# MKM33ZA5 register map
Vendor: Freescale Semiconductor, Inc.; Series: Kinetis_M; File version: 1.6
CPU: CM0PLUS r0p0, little endian, no MPU, no FPU, VTOR, 2 interrupt priority bits
Registers are 8-bit, read-write, reset 0x0 unless marked. A register's access mark holds for its fields unless they carry their own. Offsets are from the block's base; [hi:lo] are bit positions; {n}, {i} and the like mark numbered series; 'fields as' and 'values as' point back to an identical list.

## NVIC — Nested Vectored Interrupt Controller
Base 0xE000E100
0x00 NVIC_ISER 32-bit — Interrupt Set Enable Register
  [31:0] SETENA — Interrupt set enable bits
0x80 NVIC_ICER 32-bit — Interrupt Clear Enable Register
  [31:0] CLRENA — Interrupt clear-enable bits
0x100 NVIC_ISPR 32-bit — Interrupt Set Pending Register
  [31:0] SETPEND — Interrupt set-pending bits
0x180 NVIC_ICPR 32-bit — Interrupt Clear Pending Register
  [31:0] CLRPEND — Interrupt clear-pending bits
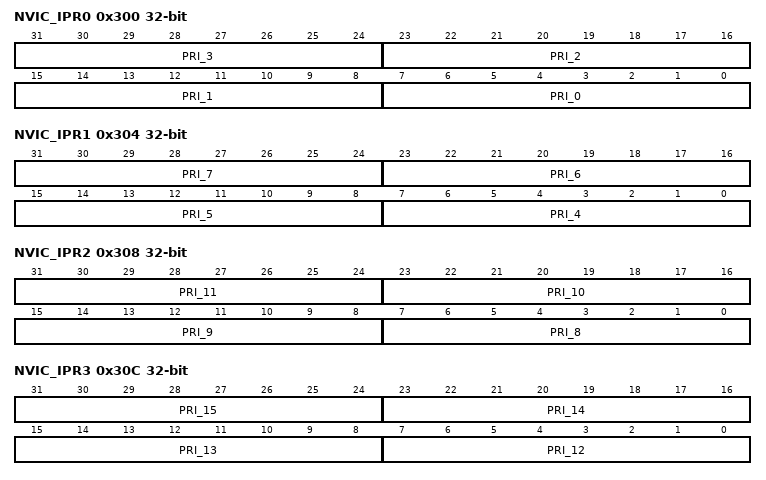
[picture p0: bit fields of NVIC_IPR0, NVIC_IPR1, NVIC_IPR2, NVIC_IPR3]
0x300 NVIC_IPR0 32-bit — Interrupt Priority Register n
  [8n+7:8n] PRI_{n} (n=0..3) — Priority of interrupt {n}
0x304 NVIC_IPR1 32-bit — Interrupt Priority Register n
  [8n-25:8n-32] PRI_{n} (n=4..7) — Priority of interrupt {n}
0x308 NVIC_IPR2 32-bit — Interrupt Priority Register n
  [8n-57:8n-64] PRI_{n} (n=8..11) — Priority of interrupt {n}
0x30C NVIC_IPR3 32-bit — Interrupt Priority Register n
  [31:24] PRI_15 — Priority of interrupt 15
  [23:16] PRI_14 — Priority of interrupt 14
  [15:8] PRI_13 — Priority of interrupt 12
  [7:0] PRI_12 — Priority of interrupt 11
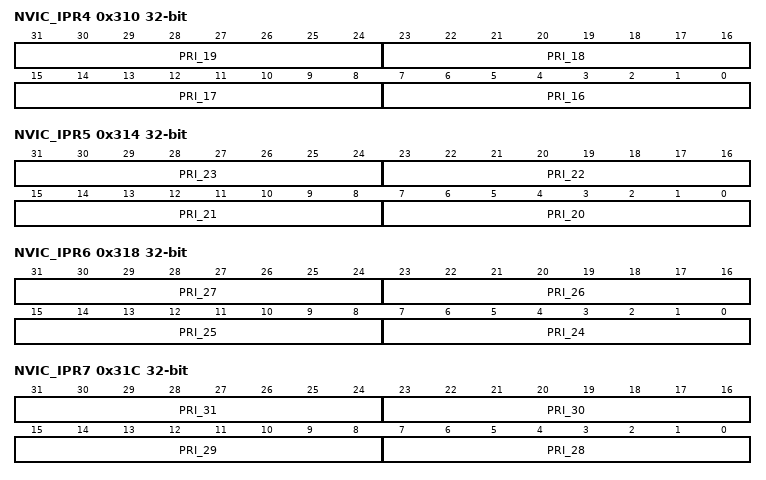
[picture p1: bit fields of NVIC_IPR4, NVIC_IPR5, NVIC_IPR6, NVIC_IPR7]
0x310 NVIC_IPR4 32-bit — Interrupt Priority Register n
  [8n-121:8n-128] PRI_{n} (n=16..19) — Priority of interrupt {n+1}
0x314 NVIC_IPR5 32-bit — Interrupt Priority Register n
  [31:24] PRI_23 — Priority of interrupt 23
  [23:16] PRI_22 — Priority of interrupt 22
  [15:8] PRI_21 — Priority of interrupt 21
  [7:0] PRI_20 — Priority of interrupt 0
0x318 NVIC_IPR6 32-bit — Interrupt Priority Register n
  [8n-185:8n-192] PRI_{n} (n=24..27) — Priority of interrupt {n}
0x31C NVIC_IPR7 32-bit — Interrupt Priority Register n
  [8n-217:8n-224] PRI_{n} (n=28..31) — Priority of interrupt {n}

## MTB — Micro Trace Buffer
Base 0xF0000000; register names take the prefix MTB_
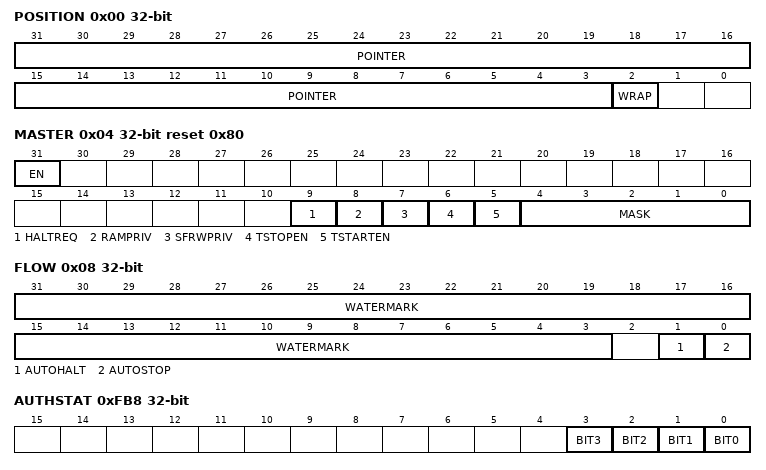
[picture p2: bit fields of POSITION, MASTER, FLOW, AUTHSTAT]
0x00 POSITION 32-bit (reset mask 0x3) — MTB Position Register
  [31:3] POINTER — Trace Packet Address Pointer[28:0]
  [2] WRAP
0x04 MASTER 32-bit reset 0x80 (reset mask 0xFFFFFFE0) — MTB Master Register
  [31] EN — Main Trace Enable
  [9] HALTREQ — Halt Request
  [8] RAMPRIV — RAM Privilege
  [7] SFRWPRIV — Special Function Register Write Privilege
  [6] TSTOPEN — Trace Stop Input Enable
  [5] TSTARTEN — Trace Start Input Enable
  [4:0] MASK
0x08 FLOW 32-bit (reset mask 0x4) — MTB Flow Register
  [31:3] WATERMARK — WATERMARK[28:0]
  [1] AUTOHALT
  [0] AUTOSTOP
0x0C BASE 32-bit ro reset not defined — MTB Base Register
  [31:0] BASEADDR
0xF00 MODECTRL 32-bit ro — Integration Mode Control Register
0xFA0 TAGSET 32-bit ro — Claim TAG Set Register
0xFA4 TAGCLEAR 32-bit ro — Claim TAG Clear Register
0xFB0 LOCKACCESS 32-bit ro
  [31:0] LOCKACCESS — Hardwired to 0x0000_0000
0xFB4 LOCKSTAT 32-bit ro — Lock Status Register
0xFB8 AUTHSTAT 32-bit ro — Authentication Status Register
  [3] BIT3
  [2] BIT2
  [1] BIT1
  [0] BIT0 — Connected to DBGEN.
0xFBC DEVICEARCH 32-bit ro reset 0x47700A31 — Device Architecture Register
0xFC8 DEVICECFG 32-bit ro — Device Configuration Register
0xFCC DEVICETYPID 32-bit ro reset 0x31 — Device Type Identifier Register
0xFD0 PERIPHID{x} (x=4,5,6,7,0,1,2,3; step 0x4) 32-bit ro reset not defined — Peripheral ID Register
  [31:0] PERIPHID
{0xFF0+4i} COMPID{i} (i=0..3) 32-bit ro reset not defined — Component ID Register
  [31:0] COMPID — Component ID

## MTBDWT — MTB data watchpoint and trace
Base 0xF0001000; register names take the prefix MTBDWT_
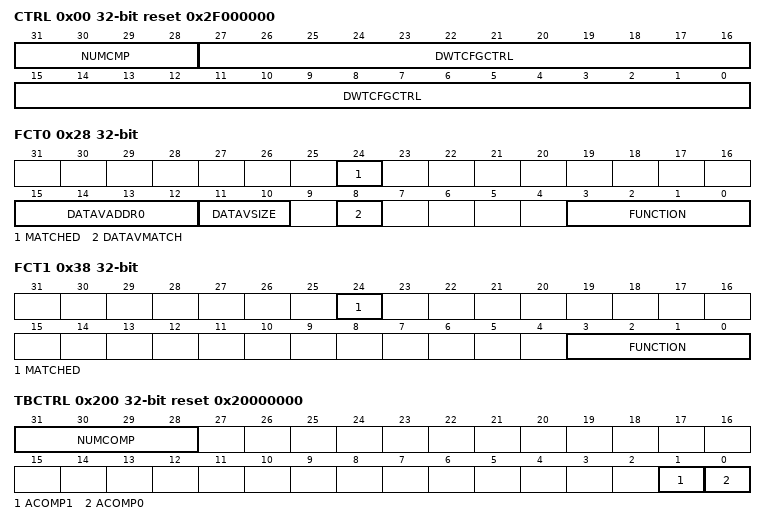
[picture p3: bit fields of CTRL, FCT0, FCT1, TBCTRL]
0x00 CTRL 32-bit ro reset 0x2F000000 — MTB DWT Control Register
  [31:28] NUMCMP — Number of comparators
  [27:0] DWTCFGCTRL — DWT configuration controls
{0x20+0x10*i} COMP{i} (i=0..1) 32-bit — MTB_DWT Comparator Register
  [31:0] COMP — Reference value for comparison
{0x24+0x10*i} MASK{i} (i=0..1) 32-bit — MTB_DWT Comparator Mask Register
  [4:0] MASK
0x28 FCT0 32-bit — MTB_DWT Comparator Function Register 0
  [24] MATCHED ro — Comparator match
    0=No match; 1=Match occurred
  [15:12] DATAVADDR0 — Data Value Address 0
  [11:10] DATAVSIZE — Data Value Size
    0=Byte; 1=Halfword; 2=Word; 3=Reserved. Any attempts to use this value results in UNPREDICTABLE behavior.
  [8] DATAVMATCH — Data Value Match
    0=Perform address comparison; 1=Perform data value comparison
  [3:0] FUNCTION
    0=Disabled; 4=Instruction fetch; 5=Data operand read; 6=Data operand write; 7=Data operand (read + write)
0x38 FCT1 32-bit — MTB_DWT Comparator Function Register 1
  [24] MATCHED ro — Comparator match
    0=No match; 1=Match occurred
  [3:0] FUNCTION
    values as FCT0.FUNCTION
0x200 TBCTRL 32-bit reset 0x20000000 — MTB_DWT Trace Buffer Control Register
  [31:28] NUMCOMP ro — Number of Comparators
  [1] ACOMP1 — Action based on Comparator 1 match
    0=Trigger TSTOP based on the assertion of MTBDWT_FCT1[MATCHED]; 1=Trigger TSTART based on the assertion of MTBDWT_FCT1[MATCHED]
  [0] ACOMP0 — Action based on Comparator 0 match
    0=Trigger TSTOP based on the assertion of MTBDWT_FCT0[MATCHED]; 1=Trigger TSTART based on the assertion of MTBDWT_FCT0[MATCHED]
0xFC8 DEVICECFG 32-bit ro — Device Configuration Register
0xFCC DEVICETYPID 32-bit ro reset 0x4 — Device Type Identifier Register
0xFD0 PERIPHID{x} (x=4,5,6,7,0,1,2,3; step 0x4) 32-bit ro reset not defined — Peripheral ID Register
  [31:0] PERIPHID
{0xFF0+4i} COMPID{i} (i=0..3) 32-bit ro reset not defined — Component ID Register
  [31:0] COMPID — Component ID

## Notices in the file
Redistribution and use in source and binary forms, with or without modification,
are permitted provided that the following conditions are met:
o Redistributions of source code must retain the above copyright notice, this list
of conditions and the following disclaimer.
o Redistributions in binary form must reproduce the above copyright notice, this
list of conditions and the following disclaimer in the documentation and/or
other materials provided with the distribution.
o Neither the name of Freescale Semiconductor, Inc. nor the names of its
contributors may be used to endorse or promote products derived from this
software without specific prior written permission.
THIS SOFTWARE IS PROVIDED BY THE COPYRIGHT HOLDERS AND CONTRIBUTORS "AS IS" AND
ANY EXPRESS OR IMPLIED WARRANTIES, INCLUDING, BUT NOT LIMITED TO, THE IMPLIED
WARRANTIES OF MERCHANTABILITY AND FITNESS FOR A PARTICULAR PURPOSE ARE
DISCLAIMED. IN NO EVENT SHALL THE COPYRIGHT HOLDER OR CONTRIBUTORS BE LIABLE FOR
ANY DIRECT, INDIRECT, INCIDENTAL, SPECIAL, EXEMPLARY, OR CONSEQUENTIAL DAMAGES
(INCLUDING, BUT NOT LIMITED TO, PROCUREMENT OF SUBSTITUTE GOODS OR SERVICES;
LOSS OF USE, DATA, OR PROFITS; OR BUSINESS INTERRUPTION) HOWEVER CAUSED AND ON
ANY THEORY OF LIABILITY, WHETHER IN CONTRACT, STRICT LIABILITY, OR TORT
(INCLUDING NEGLIGENCE OR OTHERWISE) ARISING IN ANY WAY OUT OF THE USE OF THIS
SOFTWARE, EVEN IF ADVISED OF THE POSSIBILITY OF SUCH DAMAGE.
